AUTOSAR XML (schema 4-2-2)
package /ComponentTypes
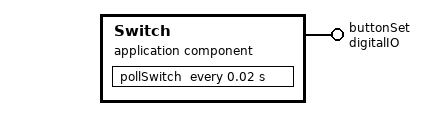
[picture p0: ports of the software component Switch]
  application sw component type Switch
    provide port buttonSet: nonqueued-sender-com-spec{data-element=boolean, init-value=0}, provided-interface=digitalIO
    behavior Switch_InternalBehavior
      timing event TMT_pollSwitch: start-on-event=pollSwitch, period=0.02
      runnable pollSwitch
        data-send-points:
          access SEND_buttonSet_boolean: accessed-variable=buttonSet.boolean
  swc implementation Switch_Implementation: behavior=Switch_InternalBehavior
